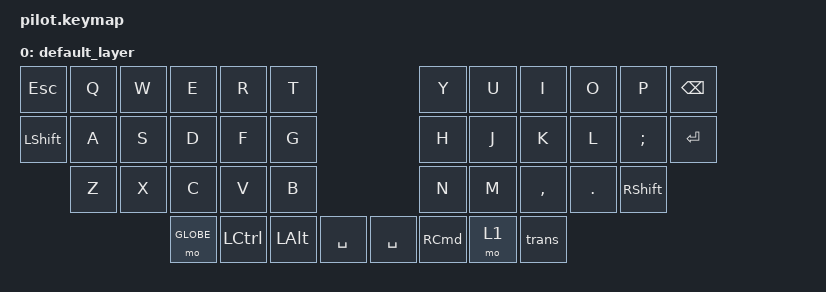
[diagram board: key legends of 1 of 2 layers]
/*
 * Copyright (c) 2020 The ZMK Contributors
 *
 * SPDX-License-Identifier: MIT
 */

// #include <pilot.dtsi>
// #include <dt-bindings/zmk/keys.h>
// #include <dt-bindings/zmk/bt.h>
#include <dt-bindings/zmk/matrix_transform.h>


/ {
        keymap {
                compatible = "zmk,keymap";

                default_layer {
// -----------------------------------------------------------------------------------------
// |  ESC |  Q  |  W  |  E  |  R   |  T  |                       |  Y  |  U   |  I  |  O  |  P   | BSPC |
// |  TAB |  A  |  S  |  D  |  F   |  G  |                       |  H  |  J   |  K  |  L  |  ;   | ENT  |
//        |  Z  |  X  |  C  |  V   |  B  |                       |  N  |  M   |  ,  |  .  | SHFT | 
//                    | FN  | CTRL | ALT | SPACE |       | SPACE | CMD | ***  | nan |
                        bindings = <
   &kp ESC   &kp Q &kp W &kp E     &kp R     &kp T                                &kp Y    &kp U  &kp I     &kp O   &kp P    &kp BSPC
   &kp LSHFT &kp A &kp S &kp D     &kp F     &kp G                                &kp H    &kp J  &kp K     &kp L   &kp SEMI &kp RET
             &kp Z &kp X &kp C     &kp V     &kp B                                &kp N    &kp M  &kp COMMA &kp DOT &kp RSHFT 
                         &mo GLOBE &kp LCTRL &kp LALT &kp SPACE         &kp SPACE &kp RCMD &mo 1 &kp trans
                        >;
                };
                lower_layer {
// -----------------------------------------------------------------------------------------
// |  TAB |  1  |  2  |  3  |  4  |  5  |   |  6  |  7  |  8  |  9  |  0  | BSPC |
// | BTCLR| BT1 | BT2 | BT3 | BT4 | BT5 |   | LFT | DWN |  UP | RGT |     |      |
// | SHFT |     |     |     |     |     |   |     |     |     |     |     |      |
//                    | GUI |     | SPC |   | ENT |     | ALT |
                        bindings = <
        &trans      &trans      &trans      &trans      &trans         &trans      &trans      &trans      &trans      &trans      &trans      &trans     
        &trans      &trans      &trans      &trans      &trans         &kp LARW    &kp DARW    &kp UARW    &kp RARW    &trans      &trans      &trans     
                    &trans      &trans      &trans      &trans         &trans      &trans      &trans      &trans      &trans       
                                &trans      &trans      &kp SPACE      &kp SPACE   &trans      &trans      &trans

                        >;
                };

//                raise_layer {
// -----------------------------------------------------------------------------------------
// |  TAB |  !  |  @  |  #  |  $  |  %  |   |  ^  |  &  |  *  |  (  |  )  | BSPC |
// | CTRL |     |     |     |     |     |   |  -  |  =  |  [  |  ]  |  \  |  `   |
// | SHFT |     |     |     |     |     |   |  _  |  +  |  {  |  }  | "|" |  ~   |
//                    | GUI |     | SPC |   | ENT |     | ALT |
//                        bindings = <
//   &kp  TAB  &kp EXCL &kp AT &kp HASH &kp DLLR &kp PRCNT   &kp CARET &kp AMPS  &kp ASTRK &kp LPAR &kp RPAR &kp BSPC
//   &kp LCTRL &trans   &trans &trans   &trans   &trans      &kp MINUS &kp EQUAL &kp LBKT  &kp RBKT &kp BSLH &kp GRAVE
//   &kp LSHFT &trans   &trans &trans   &trans   &trans      &kp UNDER &kp PLUS  &kp LBRC  &kp RBRC &kp PIPE &kp TILDE
//                             &kp LGUI &trans   &kp SPACE   &kp RET   &trans    &kp RALT
//                        >;
//                };
        };
};
